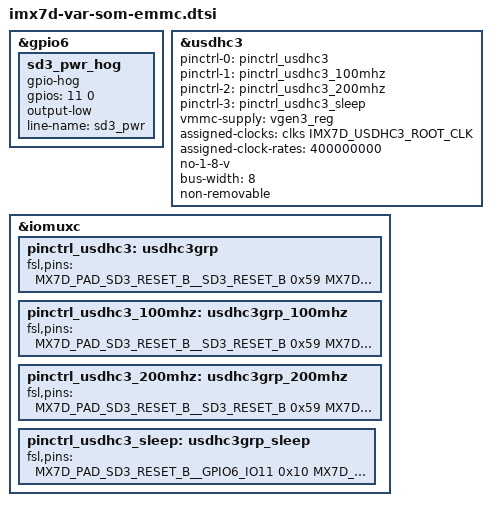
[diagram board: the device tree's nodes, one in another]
// SPDX-License-Identifier: GPL-2.0+ OR MIT
//
// Copyright (C) 2016-2022 Variscite Ltd.

&gpio6 {
	sd3_pwr_hog {
		gpio-hog;
		gpios = <11 0>;
		output-low;
		line-name = "sd3_pwr";
	};
};

&usdhc3 {
	pinctrl-names = "default", "state_100mhz", "state_200mhz", "sleep";
	pinctrl-0 = <&pinctrl_usdhc3>;
	pinctrl-1 = <&pinctrl_usdhc3_100mhz>;
	pinctrl-2 = <&pinctrl_usdhc3_200mhz>;
	pinctrl-3 = <&pinctrl_usdhc3_sleep>;
	vmmc-supply = <&vgen3_reg>;
	assigned-clocks = <&clks IMX7D_USDHC3_ROOT_CLK>;
	assigned-clock-rates = <400000000>;
	no-1-8-v;
	bus-width = <8>;
	non-removable;
	status = "okay";
};

&iomuxc {
	pinctrl_usdhc3: usdhc3grp {
		fsl,pins = <
			MX7D_PAD_SD3_RESET_B__SD3_RESET_B	0x59
			MX7D_PAD_SD3_CMD__SD3_CMD		0x59
			MX7D_PAD_SD3_CLK__SD3_CLK		0x19
			MX7D_PAD_SD3_DATA0__SD3_DATA0		0x59
			MX7D_PAD_SD3_DATA1__SD3_DATA1		0x59
			MX7D_PAD_SD3_DATA2__SD3_DATA2		0x59
			MX7D_PAD_SD3_DATA3__SD3_DATA3		0x59
			MX7D_PAD_SD3_DATA4__SD3_DATA4		0x59
			MX7D_PAD_SD3_DATA5__SD3_DATA5		0x59
			MX7D_PAD_SD3_DATA6__SD3_DATA6		0x59
			MX7D_PAD_SD3_DATA7__SD3_DATA7		0x59
		>;
	};

	pinctrl_usdhc3_100mhz: usdhc3grp_100mhz {
		fsl,pins = <
			MX7D_PAD_SD3_RESET_B__SD3_RESET_B	0x59
			MX7D_PAD_SD3_CMD__SD3_CMD		0x5a
			MX7D_PAD_SD3_CLK__SD3_CLK		0x1a
			MX7D_PAD_SD3_DATA0__SD3_DATA0		0x5a
			MX7D_PAD_SD3_DATA1__SD3_DATA1		0x5a
			MX7D_PAD_SD3_DATA2__SD3_DATA2		0x5a
			MX7D_PAD_SD3_DATA3__SD3_DATA3		0x5a
			MX7D_PAD_SD3_DATA4__SD3_DATA4		0x5a
			MX7D_PAD_SD3_DATA5__SD3_DATA5		0x5a
			MX7D_PAD_SD3_DATA6__SD3_DATA6		0x5a
			MX7D_PAD_SD3_DATA7__SD3_DATA7		0x5a
		>;
	};

	pinctrl_usdhc3_200mhz: usdhc3grp_200mhz {
		fsl,pins = <
			MX7D_PAD_SD3_RESET_B__SD3_RESET_B	0x59
			MX7D_PAD_SD3_CMD__SD3_CMD		0x5b
			MX7D_PAD_SD3_CLK__SD3_CLK		0x1b
			MX7D_PAD_SD3_DATA0__SD3_DATA0		0x5b
			MX7D_PAD_SD3_DATA1__SD3_DATA1		0x5b
			MX7D_PAD_SD3_DATA2__SD3_DATA2		0x5b
			MX7D_PAD_SD3_DATA3__SD3_DATA3		0x5b
			MX7D_PAD_SD3_DATA4__SD3_DATA4		0x5b
			MX7D_PAD_SD3_DATA5__SD3_DATA5		0x5b
			MX7D_PAD_SD3_DATA6__SD3_DATA6		0x5b
			MX7D_PAD_SD3_DATA7__SD3_DATA7		0x5b
		>;
	};

	pinctrl_usdhc3_sleep: usdhc3grp_sleep {
		fsl,pins = <
			MX7D_PAD_SD3_RESET_B__GPIO6_IO11	0x10
			MX7D_PAD_SD3_CMD__GPIO6_IO1		0x10
			MX7D_PAD_SD3_CLK__GPIO6_IO0		0x10
			MX7D_PAD_SD3_DATA0__GPIO6_IO2		0x10
			MX7D_PAD_SD3_DATA1__GPIO6_IO3		0x10
			MX7D_PAD_SD3_DATA2__GPIO6_IO4		0x10
			MX7D_PAD_SD3_DATA3__GPIO6_IO5		0x10
			MX7D_PAD_SD3_DATA4__GPIO6_IO6		0x10
			MX7D_PAD_SD3_DATA5__GPIO6_IO7		0x10
			MX7D_PAD_SD3_DATA6__GPIO6_IO8		0x10
			MX7D_PAD_SD3_DATA7__GPIO6_IO9		0x10
		>;
	};
};
